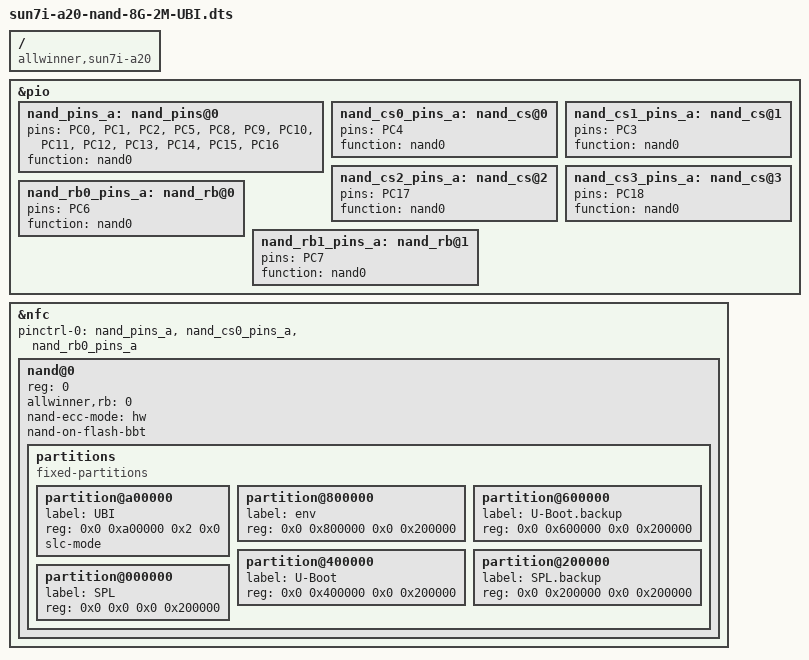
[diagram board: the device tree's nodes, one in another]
/dts-v1/;
/plugin/;

/ {
	compatible = "allwinner,sun7i-a20";

	fragment@0 {
		target = <&pio>;
		__overlay__ {
			nand_pins_a: nand_pins@0 {
				pins = "PC0", "PC1", "PC2",
						"PC5", "PC8", "PC9", "PC10",
						"PC11", "PC12", "PC13", "PC14",
						"PC15", "PC16";
				function = "nand0";
			};

			nand_cs0_pins_a: nand_cs@0 {
				pins = "PC4";
				function = "nand0";
			};

			nand_cs1_pins_a: nand_cs@1 {
				pins = "PC3";
				function = "nand0";
			};

			nand_cs2_pins_a: nand_cs@2 {
				pins = "PC17";
				function = "nand0";
			};

			nand_cs3_pins_a: nand_cs@3 {
				pins = "PC18";
				function = "nand0";
			};

			nand_rb0_pins_a: nand_rb@0 {
				pins = "PC6";
				function = "nand0";
			};

			nand_rb1_pins_a: nand_rb@1 {
				pins = "PC7";
				function = "nand0";
			};
		};
	};

	fragment@1 {
		target = <&nfc>;
		__overlay__ {
			#address-cells = <1>;
			#size-cells = <0>;
			pinctrl-names = "default";
			pinctrl-0 = <&nand_pins_a>, <&nand_cs0_pins_a>, <&nand_rb0_pins_a>;
			status = "okay";

			nand@0 {
				reg = <0>;
				allwinner,rb = <0>;
				nand-ecc-mode = "hw";
				nand-on-flash-bbt;

				partitions {
					compatible = "fixed-partitions";
					#address-cells = <2>;
					#size-cells = <2>;
					
					/*
					   List partitions in reverse order,
					   since for some reason mtd device numbers
					   start with last partition first.
					   
					   Each boot partition is of 1 blocksize.
					   In this case it is configured for a 2M blocksize NAND.
					   The rootfs partition is configured for a MLC NAND
					   with SLC emulation mode to leverage UBI.
					*/

					partition@a00000 {	/* /dev/mtd5 */
						label = "UBI";
						reg = <0x0 0xa00000 0x2 0x0>;
						slc-mode; /* UBI requires SLC mode for MLC NAND */
					};

					partition@800000 {	/* dev/mtd4 */
						label = "env";
						reg = <0x0 0x800000 0x0 0x200000>;
					};

					partition@600000 {	/* dev/mtd3 */
						label = "U-Boot.backup";
						reg = <0x0 0x600000 0x0 0x200000>;
					};

					partition@400000 {	/* dev/mtd2 */
						label = "U-Boot";
						reg = <0x0 0x400000 0x0 0x200000>;
					};

					partition@200000 {	/* dev/mtd1 */
						label = "SPL.backup";
						reg = <0x0 0x200000 0x0 0x200000>;
					};

					partition@000000 {	/* dev/mtd0 */
						label = "SPL";
						reg = <0x0 0x0 0x0 0x200000>;
					};
				};
			};
		};
	};
};
